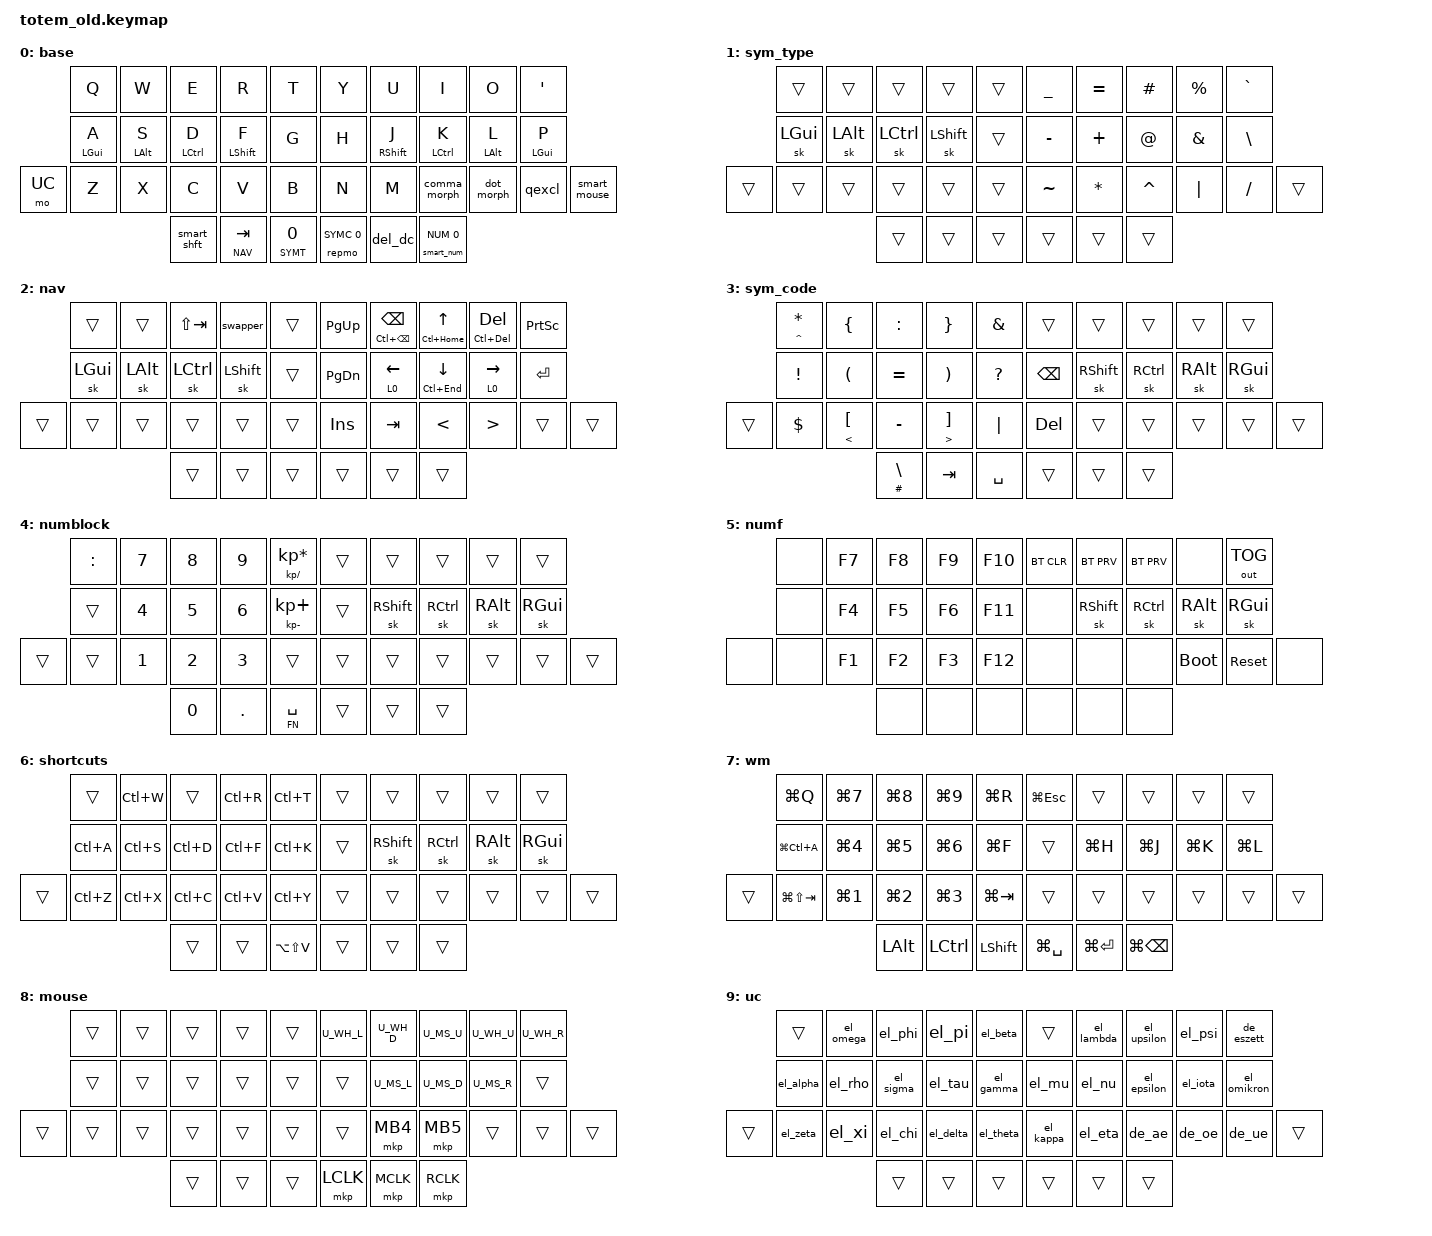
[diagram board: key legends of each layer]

#include <behaviors.dtsi>
#include <dt-bindings/zmk/bt.h>
#include <dt-bindings/zmk/keys.h>
#include <dt-bindings/zmk/outputs.h>

#include "../zmk-nodefree-config/keypos_def/keypos_38keys.h"

#include "../zmk-nodefree-config/helper.h"
#include "../zmk-nodefree-config/international_chars/german.dtsi"
#include "../zmk-nodefree-config/international_chars/greek.dtsi"

#include "mouse.dtsi"

#define DEF 0
#define SYMT 1
#define NAV 2
#define SYMC 3
#define NUM 4
#define FN 5
#define SC 6
#define IDEA 7
#define WM 8
#define MOUSE 9
#define UC 10

#include "combos.dtsi"  // requires layer aliases

#define XXXX &none
#define ____ &trans

#define QUICK_TAP_MS 175

&sk {  // sticky-key config
    release-after-ms = <900>;  // release after 0.6s
    quick-release;             // no double capitalization when rolling keys
};

&sl {  // sticky-layer config
    ignore-modifiers;          // allow chording sticky mods & layers
};

&lt {  // layer-tap config
    flavor = "balanced";
    tapping-term-ms = <200>;
    quick-tap-ms = <QUICK_TAP_MS>;
};


/* Homerow mods */

#define KEYS_L LT0 LT1 LT2 LT3 LT4 LM0 LM1 LM2 LM3 LM4 LB0 LB1 LB2 LB3 LB4  // left hand
#define KEYS_R RT0 RT1 RT2 RT3 RT4 RM0 RM1 RM2 RM3 RM4 RB0 RB1 RB2 RB3 RB4 // right hand
#define THUMBS LH2 LH1 LH0 RH0 RH1 RH2                                      // thumbs

#define MAKE_HRM(NAME, HOLD, TAP, TRIGGER_POS) \
    ZMK_BEHAVIOR(NAME, hold_tap, \
        flavor = "balanced"; \
        tapping-term-ms = <280>; \
        quick-tap-ms = <QUICK_TAP_MS>; \
        require-prior-idle-ms = <150>; \
        bindings = <HOLD>, <TAP>; \
        hold-trigger-key-positions = <TRIGGER_POS>; \
        hold-trigger-on-release; \
    )

MAKE_HRM(hml, &kp, &kp, KEYS_R THUMBS)  // left-hand HRMs
MAKE_HRM(hmr, &kp, &kp, KEYS_L THUMBS)  // right-hand HRMs

MAKE_HRM(hml_repeat, &kp, &key_repeat, KEYS_R THUMBS)  // used for HRM-combo
MAKE_HRM(hmr_lpar_lt, &kp, &lpar_lt, KEYS_L THUMBS)    // "    "   "   "
MAKE_HRM(hmr_rpar_gt, &kp, &rpar_gt, KEYS_L THUMBS)    // "    "   "   "


/* Nav cluster */

// long-tap action on hold, short-tap action on all interrupts
#define MT_CORE \
    flavor = "tap-preferred"; \
    tapping-term-ms = <220>; \
    quick-tap-ms = <220>; \
    hold-trigger-key-positions = <0>;\

&mt { MT_CORE };
ZMK_BEHAVIOR(mt_home, hold_tap, bindings = <&masked_home>, <&kp>; MT_CORE)
ZMK_BEHAVIOR(mt_end,  hold_tap,  bindings = <&masked_end>, <&kp>; MT_CORE)

#define NAV_LEFT  &mt_home 0   LEFT    // tap: left  | long-tap: beginning of line
#define NAV_RIGHT &mt_end 0    RIGHT   // tap: right | long-tap: end       of line
#define NAV_UP    &mt LC(HOME) UP      // tap: up    | long-tap: beginning of document
#define NAV_DOWN  &mt LC(END)  DOWN    // tap: down  | long-tap: end       of document
#define NAV_BSPC  &mt LC(BSPC) BSPC    // tap: bspc  | long-tap: delete word backward
#define NAV_DEL   &mt LC(DEL)  DEL     // tap: del   | long-tap: delete word forward

// mask CTRL when holding left/right to avoid accidental jumps to beginning/end of document
#define MASK_MODS(NAME, MODS, BINDING) \
    ZMK_BEHAVIOR(NAME, mod_morph, \
        bindings = <BINDING>, <BINDING>; \
        mods = <MODS>; \
    )

MASK_MODS(masked_home, (MOD_LCTL), &kp HOME)
MASK_MODS(masked_end,  (MOD_LCTL), &kp END)

/* Caps-word, num-word and smart-mouse */

// tap: sticky-shift | shift + tap/ double-tap: caps-word | hold: shift
ZMK_BEHAVIOR(smart_shft, mod_morph,
    bindings = <&sk LSHFT>, <&caps_word>;
    mods = <(MOD_LSFT)>;
)
&caps_word {  // mods deactivate caps-word, requires PR #1451
    /delete-property/ ignore-modifiers;
};

// tap: num-word | double-tap: sticky num-layer | hold: num-layer
#define SMART_NUM &smart_num NUM 0
ZMK_BEHAVIOR(smart_num, hold_tap,
    flavor = "balanced";
    tapping-term-ms = <200>;
    quick-tap-ms = <QUICK_TAP_MS>;
    bindings = <&mo>, <&num_dance>;
)
ZMK_BEHAVIOR(num_dance, tap_dance,
    tapping-term-ms = <200>;
    bindings = <&num_word>, <&sl NUM>;  // reverse this for sticky-num on single tap
)
&num_word {  // num-word, requires PR #1451
    layers = <NUM>;
    continue-list = <BSPC DEL DOT COMMA PLUS MINUS STAR FSLH EQUAL>;
};

// smart-mouse, requires PR #1366
ZMK_BEHAVIOR(smart_mouse, tri_state,
    bindings = <&tog MOUSE>, <____ >, <&tog MOUSE>;
    ignored-key-positions = <LT1 LT3 RT1 RT2 RT3 RM1 RM2 RM3 RH0 RH1 RH2>;
    ignored-layers = <MOUSE>;
)

/* Custom behaviors */

// Alt+Tab swapper, requires PR #1366
ZMK_BEHAVIOR(swapper, tri_state,
    bindings = <&kt LGUI>, <&kp TAB>, <&kt LGUI>;
    ignored-key-positions = <LT2>;
)

// Sticky layer + sticky shift (workaround for issue #1421)
ZMK_BEHAVIOR(sls, sticky_key,
    release-after-ms = <1000>;
    bindings = <&uc_shift>;
    ignore-modifiers;
)
ZMK_BEHAVIOR(uc_shift, macro,
    wait-ms = <0>;
    tap-ms = <1>;
    bindings = <&macro_press &mo UC &kp LSHFT>
             , <&macro_pause_for_release>
             , <&macro_release &mo UC &kp LSHFT>;
)

// reuse basic mod-morph scheme
#define SIMPLE_MORPH(NAME, MOD, BINDING1, BINDING2) \
    ZMK_BEHAVIOR(NAME, mod_morph, \
        mods = <(MOD_L ## MOD|MOD_R ## MOD)>; \
        bindings = <BINDING1>, <BINDING2>; \
    )

// tap: comma | shift + tap: semicolon | ctrl + shift + tap: <
SIMPLE_MORPH(comma_morph, SFT, &kp COMMA, &comma_inner_morph)
SIMPLE_MORPH(comma_inner_morph, CTL, &kp SEMICOLON, &kp LESS_THAN)

// tap: dot | shift + tap: colon | ctrl + shift + tap: >
SIMPLE_MORPH(dot_morph, SFT, &kp DOT, &dot_inner_morph)
SIMPLE_MORPH(dot_inner_morph, CTL, &kp COLON, &kp GREATER_THAN)

// tap: qmark | shift + tap: excl
SIMPLE_MORPH(qexcl, SFT, &kp QMARK, &kp EXCL)

// tap: left/right parenthesis | shft + tap: less-than/greater-than
SIMPLE_MORPH(lpar_lt, SFT, &kp LPAR, &kp LT)
SIMPLE_MORPH(rpar_gt, SFT, &kp RPAR, &kp GT)

// tap: space | shift + tap: dot -> space -> sticky shift | hold: activate layer
ZMK_BEHAVIOR(lt_spc, hold_tap,
    flavor = "balanced";
    tapping-term-ms = <200>;
    quick-tap-ms = <QUICK_TAP_MS>;
    bindings = <&mo>, <&spc_morph>;
)
SIMPLE_MORPH(spc_morph, SFT, &kp SPACE, &dot_spc)
ZMK_BEHAVIOR(dot_spc, macro,
    wait-ms = <0>;
    tap-ms = <5>;
    bindings = <&kp DOT &kp SPACE &sk LSHFT>;
)

// tap: backspace | lshft + tap: delete | rshft + tap: shift-delete
ZMK_BEHAVIOR(bs_del, mod_morph,
    bindings = <&kp BSPC>, <&kp DEL>;
    mods = <(MOD_LSFT|MOD_RSFT)>;
    keep-mods = <MOD_RSFT>;
)

// tap: bs_del | double-tap: ctrl + backspace
ZMK_BEHAVIOR(del_dc, tap_dance,
    tapping-term-ms = <200>;
    bindings = <&bs_del>, <&kp LC(BSPC)>;
)

// tap: copy | double-tap: cut
ZMK_BEHAVIOR(copy_cut, tap_dance,
    tapping-term-ms = <200>;
    bindings = <&kp LC(INS)>, <&kp LC(X)>;
)

// tap: paste | double-tap: alt shift v
ZMK_BEHAVIOR(paste_q, tap_dance,
    tapping-term-ms = <200>;
    bindings = <&kp LC(V)>, <&kp LS(LA(V))>;
)

ZMK_BEHAVIOR(mo_tog, hold_tap,
    tapping-term-ms = <200>;
    quick-tap-ms = <QUICK_TAP_MS>;
    bindings = <&mo>, <&tog>;
    require-prior-idle-ms = <100>;
)

ZMK_BEHAVIOR(repmo, hold_tap,
    tapping-term-ms = <200>;
    quick-tap-ms = <QUICK_TAP_MS>;
    bindings = <&mo>, <&key_repeat>;
    require-prior-idle-ms = <100>;
)

ZMK_UNICODE_SINGLE(eur, N2, N0, A, C)

ZMK_LAYER(base,
//         ╭─────────────┬─────────────┬─────────────┬─────────────┬─────────────╮ ╭──────╮ ╭─────────────┬─────────────┬─────────────┬─────────────┬─────────────╮
             &kp Q         &kp W         &kp E         &kp R         &kp T                    &kp Y         &kp U         &kp I         &kp O         &kp SQT
//         ├─────────────┼─────────────┼─────────────┼─────────────┼─────────────┤ ├──────┤ ├─────────────┼─────────────┼─────────────┼─────────────┼─────────────┤
             &hml LGUI A   &hml LALT S   &hml LCTRL D  &hml LSHFT F  &kp G                    &kp H         &hmr RSHFT J  &hmr LCTRL K  &hmr LALT L   &hmr LGUI P
//╭──────┤ ├─────────────┼─────────────┼─────────────┼─────────────┼─────────────┤ ├──────┤ ├─────────────┼─────────────┼─────────────┼─────────────┼─────────────┤ ├──────╮
    &mo UC   &kp Z         &kp X         &kp C         &kp V         &kp B                    &kp N         &kp M         &comma_morph  &dot_morph    &qexcl          &smart_mouse
//╰──────┤ ╰─────────────┼─────────────┴─────────────┼─────────────┼─────────────┤ ├──────┤ ├─────────────┼─────────────┼─────────────┴───────────────────────────╯ ├──────╯
                                         &smart_shft   &lt NAV TAB   &lt_spc SYMT 0           &repmo SYMC 0 &del_dc       SMART_NUM
//                                     ╰─────────────┴─────────────┴─────────────╯ ╰──────╯ ╰─────────────┴─────────────┴─────────────╯
)

ZMK_LAYER(sym_type,
//         ╭─────────────┬─────────────┬─────────────┬─────────────┬─────────────╮ ╭──────╮ ╭─────────────┬─────────────┬─────────────┬─────────────┬─────────────╮
             ____          ____          ____          ____          ____                     &kp UNDER     &kp EQUAL     &kp HASH      &kp PERCENT   &kp GRAVE
//         ├─────────────┼─────────────┼─────────────┼─────────────┼─────────────┤ ├──────┤ ├─────────────┼─────────────┼─────────────┼─────────────┼─────────────┤
             &sk LGUI      &sk LALT      &sk LCTRL     &sk LSHFT     ____                     &kp MINUS     &kp PLUS      &kp AT        &kp AMPS      &kp BSLH
//╭──────┤ ├─────────────┼─────────────┼─────────────┼─────────────┼─────────────┤ ├──────┤ ├─────────────┼─────────────┼─────────────┼─────────────┼─────────────┤ ├──────╮
    ____     ____          ____          ____          ____          ____                     &kp TILDE     &kp STAR      &kp CARET     &kp PIPE      &kp FSLH        ____
//╰──────┤ ╰─────────────┼─────────────┴─────────────┼─────────────┼─────────────┤ ├──────┤ ├─────────────┼─────────────┼─────────────┴───────────────────────────╯ ├──────╯
                                         ____          ____          ____                     ____           ____           ____
//                                     ╰─────────────┴─────────────┴─────────────╯ ╰──────╯ ╰─────────────┴─────────────┴─────────────╯
)

ZMK_LAYER(nav,
//         ╭─────────────┬─────────────┬─────────────┬─────────────┬─────────────╮ ╭──────╮ ╭─────────────┬─────────────┬─────────────┬─────────────┬─────────────╮
             ____          ____          &kp LS(TAB)   &swapper      ____                     &kp PG_UP     NAV_BSPC      NAV_UP        NAV_DEL       &kp PRINTSCREEN
//         ├─────────────┼─────────────┼─────────────┼─────────────┼─────────────┤ ├──────┤ ├─────────────┼─────────────┼─────────────┼─────────────┼─────────────┤
             &sk LGUI      &sk LALT      &sk LCTRL     &sk LSHFT     ____                     &kp PG_DN     NAV_LEFT      NAV_DOWN      NAV_RIGHT     &kp RET
//╭──────┤ ├─────────────┼─────────────┼─────────────┼─────────────┼─────────────┤ ├──────┤ ├─────────────┼─────────────┼─────────────┼─────────────┼─────────────┤ ├──────╮
    ____     ____          ____          ____          ____          ____                     &kp INS       &kp TAB       &kp LT        &kp GT        ____             ____
//╰──────┤ ╰─────────────┼─────────────┴─────────────┼─────────────┼─────────────┤ ├──────┤ ├─────────────┼─────────────┼─────────────┴───────────────────────────╯ ├──────╯
                                         ____          ____          ____                     ____           ____           ____
//                                     ╰─────────────┴─────────────┴─────────────╯ ╰──────╯ ╰─────────────┴─────────────┴─────────────╯
)

ZMK_LAYER(sym_code,
       &mt CARET ASTERISK  &kp LEFT_BRACE              &kp COLON           &kp RIGHT_BRACE                 &kp AMPERSAND    ____           ____       ____       ____      ____
       &kp EXCLAMATION     &kp LEFT_PARENTHESIS        &kp EQUAL           &kp RIGHT_PARENTHESIS           &kp QUESTION     &kp BACKSPACE  &sk RSHFT  &sk RCTRL  &sk RALT  &sk RGUI
____   &kp DOLLAR          &mt LESS_THAN LEFT_BRACKET  &kp MINUS           &mt GREATER_THAN RIGHT_BRACKET  &kp PIPE         &kp DELETE     ____       ____       ____      ____      ____
                                                       &mt HASH BACKSLASH  &kp TAB                         &kp SPACE        ____           ____       ____
)

ZMK_LAYER(numblock,
       &kp COLON  &kp N7  &kp N8  &kp N9      &mt KP_DIVIDE KP_MULTIPLY    ____  ____       ____       ____      ____
       ____       &kp N4  &kp N5  &kp N6      &mt KP_SUBTRACT KP_PLUS      ____  &sk RSHFT  &sk RCTRL  &sk RALT  &sk RGUI
____   ____       &kp N1  &kp N2  &kp N3      ____                         ____  ____       ____       ____      ____      ____
                          &kp N0  &kp DOT  &lt FN SPACE                 ____           ____       ____
)

ZMK_LAYER(numf,
       &none  &kp F7  &kp F8  &kp F9  &kp F10    &bt BT_CLR  &bt BT_PRV  &bt BT_PRV  &none        &out OUT_TOG
       &none  &kp F4  &kp F5  &kp F6  &kp F11    &none       &sk RSHFT   &sk RCTRL   &sk RALT     &sk RGUI
&none  &none  &kp F1  &kp F2  &kp F3  &kp F12    &none       &none       &none       &bootloader  &sys_reset    &none
                      &none   &none   &none      &none       &none       &none
)

ZMK_LAYER(shortcuts,
       ____       &kp LC(W)  ____       &kp LC(R)  &kp LC(T)    ____   ____       ____       ____      ____
       &kp LC(A)  &kp LC(S)  &kp LC(D)  &kp LC(F)  &kp LC(K)    ____   &sk RSHFT  &sk RCTRL  &sk RALT  &sk RGUI
____   &kp LC(Z)  &kp LC(X)  &kp LC(C)  &kp LC(V)  &kp LC(Y)    ____   ____       ____       ____      ____      ____
                             ____       ____       &kp LA(LS(V))     ____   ____       ____
)
ZMK_LAYER(idea,
       &kp F2         ____           &kp F6         &kp LA(F7)     ____                 ____   ____   ____   ____   ____
       &kp LS(LSHFT)  &kp LC(N)      &kp LS(LC(N))  &kp LS(LC(A))  &kp LS(LC(LA(T)))    ____   ____   ____   ____   ____
&to 0  &kp LA(LC(M))  &kp LA(LC(P))  &kp LA(LC(C))  &kp LA(LC(V))  ____                 ____   ____   ____   ____   ____   ____
                                     ____           ____           ____                 ____   ____   ____
)
ZMK_LAYER(wm,
       &kp LG(Q)        &kp LG(N7)  &kp LG(N8)  &kp LG(N9)  &kp LG(R)      &kp LG(ESCAPE)  ____           ____               ____       ____
       &kp LG(LC(A))    &kp LG(N4)  &kp LG(N5)  &kp LG(N6)  &kp LG(F)      ____            &kp LG(H)      &kp LG(J)          &kp LG(K)  &kp LG(L)
____   &kp LG(LS(TAB))  &kp LG(N1)  &kp LG(N2)  &kp LG(N3)  &kp LG(TAB)    ____            ____           ____               ____       ____       ____
                                    &kp LALT    &kp LCTRL   &kp LSHFT      &kp LG(SPACE)   &kp LG(ENTER)  &kp LG(BACKSPACE)
)


ZMK_LAYER(mouse,
//╭──────╮ ╭─────────────┬─────────────┬─────────────┬─────────────┬─────────────╮ ╭──────╮ ╭─────────────┬─────────────┬─────────────┬─────────────┬─────────────╮ ╭──────╮
             ____           ____           ____           ____           ____                      U_WH_L             U_WH_D        U_MS_U         U_WH_U       U_WH_R
//├──────┤ ├─────────────┼─────────────┼─────────────┼─────────────┼─────────────┤ ├──────┤ ├─────────────┼─────────────┼─────────────┼─────────────┼─────────────┤ ├──────┤
             ____           ____           ____           ____           ____                      ____           U_MS_L        U_MS_D         U_MS_R       ____
//├──────┤ ├─────────────┼─────────────┼─────────────┼─────────────┼─────────────┤ ├──────┤ ├─────────────┼─────────────┼─────────────┼─────────────┼─────────────┤ ├──────┤
    ____     ____           ____           ____           ____           ____                      ____            &mkp MB4            &mkp MB5            ____          ____             ____
//├──────┤ ╰─────────────┼─────────────┴─────────────┼─────────────┼─────────────┤ ├──────┤ ├─────────────┼─────────────┼─────────────┴───────────────────────────╯ ├──────┤
                                         ____           ____           ____                       &mkp LCLK        &mkp MCLK        &mkp RCLK
//╰──────╯                                           ╰─────────────┴─────────────╯ ╰──────╯ ╰─────────────┴─────────────╯                                           ╰──────╯
)


ZMK_LAYER(uc,
//╭──────╮ ╭─────────────┬─────────────┬─────────────┬─────────────┬─────────────╮ ╭──────╮ ╭─────────────┬─────────────┬─────────────┬─────────────┬─────────────╮ ╭──────╮
             ____           &el_omega     &el_phi       &el_pi        &el_beta                 ____           &el_lambda    &el_upsilon   &el_psi       &de_eszett
//├──────┤ ├─────────────┼─────────────┼─────────────┼─────────────┼─────────────┤ ├──────┤ ├─────────────┼─────────────┼─────────────┼─────────────┼─────────────┤ ├──────┤
             &el_alpha     &el_rho       &el_sigma     &el_tau       &el_gamma                &el_mu        &el_nu        &el_epsilon   &el_iota      &el_omikron
//├──────┤ ├─────────────┼─────────────┼─────────────┼─────────────┼─────────────┤ ├──────┤ ├─────────────┼─────────────┼─────────────┼─────────────┼─────────────┤ ├──────┤
    ____     &el_zeta      &el_xi        &el_chi       &el_delta     &el_theta                &el_kappa     &el_eta       &de_ae        &de_oe        &de_ue          ____
//├──────┤ ╰─────────────┼─────────────┴─────────────┼─────────────┼─────────────┤ ├──────┤ ├─────────────┼─────────────┼─────────────┴───────────────────────────╯ ├──────┤
                                         ____           ____           ____                      ____           ____           ____
//╰──────╯                                           ╰─────────────┴─────────────╯ ╰──────╯ ╰───────────────────────────╯                                           ╰──────╯
)
